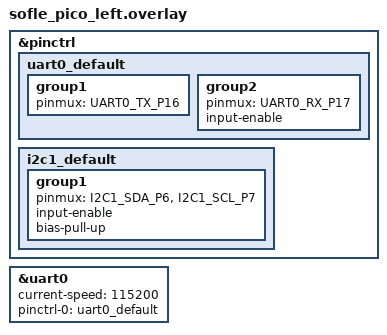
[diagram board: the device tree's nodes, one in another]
#include "sofle_pico.dtsi"
#include <zephyr/dt-bindings/gpio/gpio.h>
#include <dt-bindings/pinctrl/rpi-pico-rp2350a-pinctrl.h>
 
&pinctrl {
    uart0_default: uart0_default {
        group1 {
            pinmux = <UART0_TX_P16>;
        };
        group2 {
            pinmux = <UART0_RX_P17>;
            input-enable;
        };
    };
 
    i2c1_default: i2c1_default {
        group1 {
            pinmux = <I2C1_SDA_P6>, <I2C1_SCL_P7>;
            input-enable;
            bias-pull-up;
        };
    };
};
 
&uart0 {
    status = "okay";
    current-speed = <115200>;
    pinctrl-0 = <&uart0_default>;
    pinctrl-names = "default";
};
 
